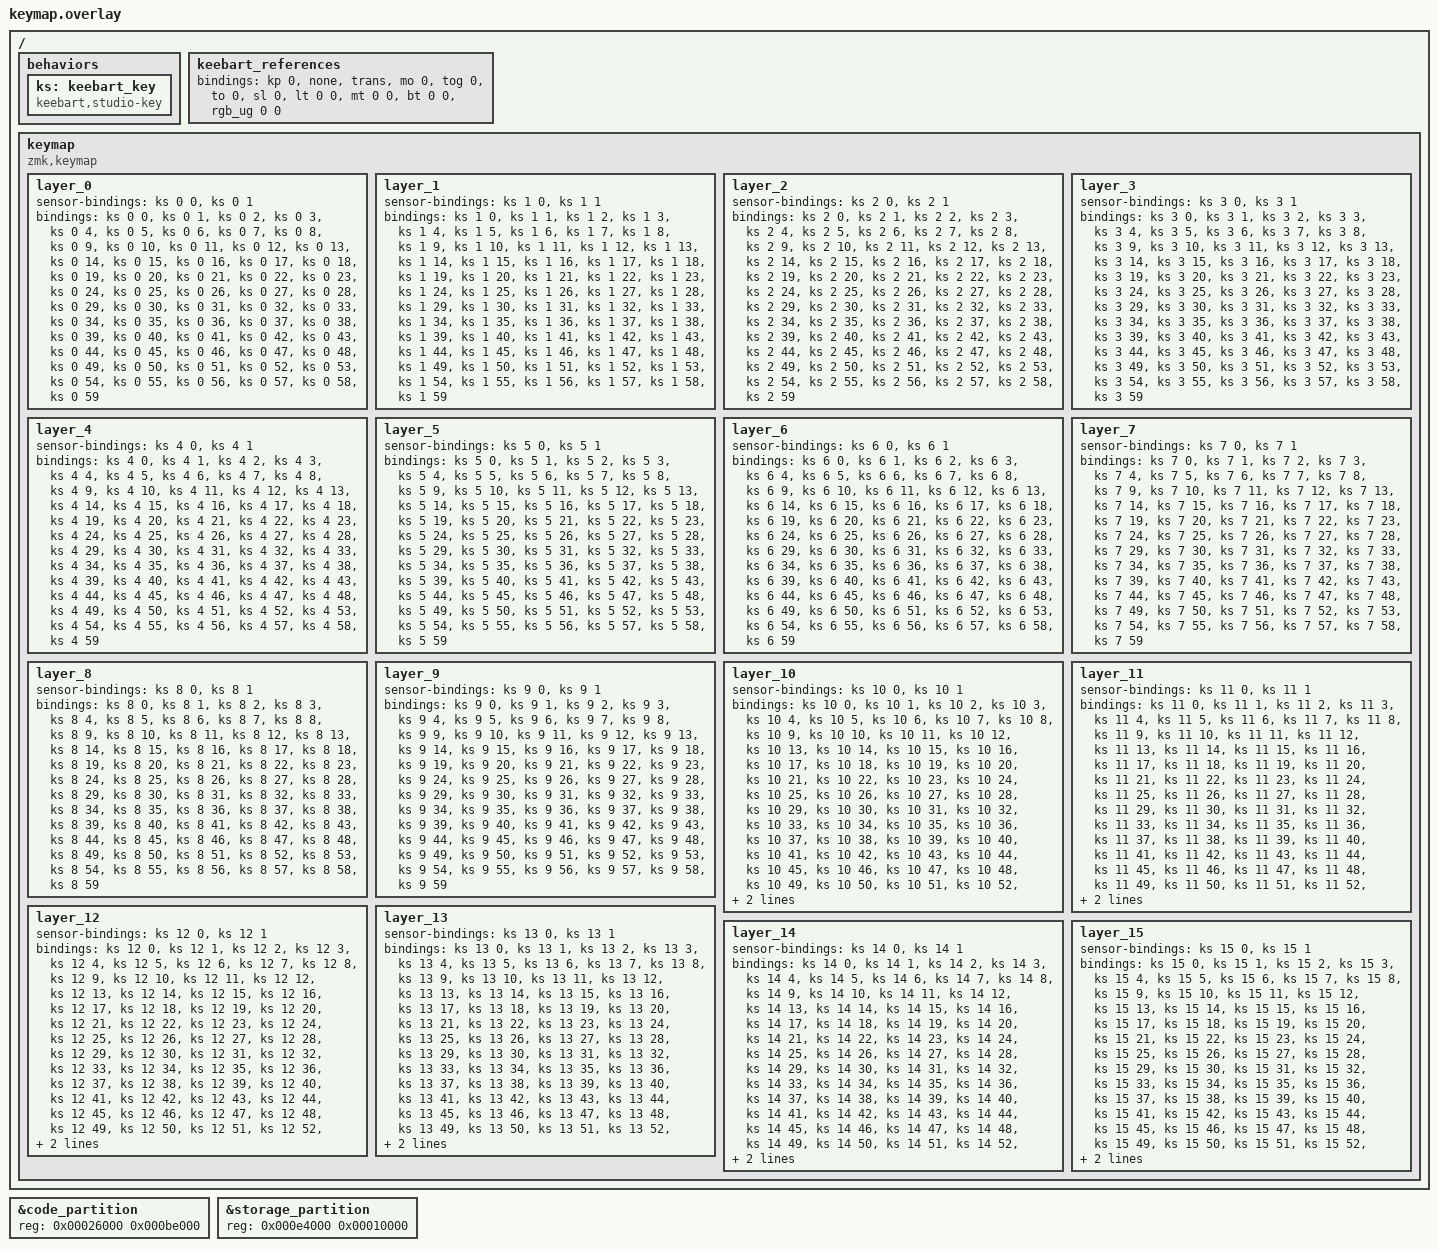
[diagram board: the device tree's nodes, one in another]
#include <behaviors.dtsi>
/ { /delete-node/ keymap; /delete-node/ conditional_layers; };
/ {
 behaviors { ks: keebart_key { compatible = "keebart,studio-key"; #binding-cells = <2>; #sensor-binding-cells = <2>; }; };
 keebart_references { bindings = <&kp 0 &none &trans &mo 0 &tog 0 &to 0 &sl 0 &lt 0 0 &mt 0 0 &bt 0 0 &rgb_ug 0 0>; };
 keymap { compatible = "zmk,keymap";
 layer_0 { sensor-bindings = <&ks 0 0 &ks 0 1>; bindings = <&ks 0 0 &ks 0 1 &ks 0 2 &ks 0 3 &ks 0 4 &ks 0 5 &ks 0 6 &ks 0 7 &ks 0 8 &ks 0 9 &ks 0 10 &ks 0 11 &ks 0 12 &ks 0 13 &ks 0 14 &ks 0 15 &ks 0 16 &ks 0 17 &ks 0 18 &ks 0 19 &ks 0 20 &ks 0 21 &ks 0 22 &ks 0 23 &ks 0 24 &ks 0 25 &ks 0 26 &ks 0 27 &ks 0 28 &ks 0 29 &ks 0 30 &ks 0 31 &ks 0 32 &ks 0 33 &ks 0 34 &ks 0 35 &ks 0 36 &ks 0 37 &ks 0 38 &ks 0 39 &ks 0 40 &ks 0 41 &ks 0 42 &ks 0 43 &ks 0 44 &ks 0 45 &ks 0 46 &ks 0 47 &ks 0 48 &ks 0 49 &ks 0 50 &ks 0 51 &ks 0 52 &ks 0 53 &ks 0 54 &ks 0 55 &ks 0 56 &ks 0 57 &ks 0 58 &ks 0 59>; };
 layer_1 { sensor-bindings = <&ks 1 0 &ks 1 1>; bindings = <&ks 1 0 &ks 1 1 &ks 1 2 &ks 1 3 &ks 1 4 &ks 1 5 &ks 1 6 &ks 1 7 &ks 1 8 &ks 1 9 &ks 1 10 &ks 1 11 &ks 1 12 &ks 1 13 &ks 1 14 &ks 1 15 &ks 1 16 &ks 1 17 &ks 1 18 &ks 1 19 &ks 1 20 &ks 1 21 &ks 1 22 &ks 1 23 &ks 1 24 &ks 1 25 &ks 1 26 &ks 1 27 &ks 1 28 &ks 1 29 &ks 1 30 &ks 1 31 &ks 1 32 &ks 1 33 &ks 1 34 &ks 1 35 &ks 1 36 &ks 1 37 &ks 1 38 &ks 1 39 &ks 1 40 &ks 1 41 &ks 1 42 &ks 1 43 &ks 1 44 &ks 1 45 &ks 1 46 &ks 1 47 &ks 1 48 &ks 1 49 &ks 1 50 &ks 1 51 &ks 1 52 &ks 1 53 &ks 1 54 &ks 1 55 &ks 1 56 &ks 1 57 &ks 1 58 &ks 1 59>; };
 layer_2 { sensor-bindings = <&ks 2 0 &ks 2 1>; bindings = <&ks 2 0 &ks 2 1 &ks 2 2 &ks 2 3 &ks 2 4 &ks 2 5 &ks 2 6 &ks 2 7 &ks 2 8 &ks 2 9 &ks 2 10 &ks 2 11 &ks 2 12 &ks 2 13 &ks 2 14 &ks 2 15 &ks 2 16 &ks 2 17 &ks 2 18 &ks 2 19 &ks 2 20 &ks 2 21 &ks 2 22 &ks 2 23 &ks 2 24 &ks 2 25 &ks 2 26 &ks 2 27 &ks 2 28 &ks 2 29 &ks 2 30 &ks 2 31 &ks 2 32 &ks 2 33 &ks 2 34 &ks 2 35 &ks 2 36 &ks 2 37 &ks 2 38 &ks 2 39 &ks 2 40 &ks 2 41 &ks 2 42 &ks 2 43 &ks 2 44 &ks 2 45 &ks 2 46 &ks 2 47 &ks 2 48 &ks 2 49 &ks 2 50 &ks 2 51 &ks 2 52 &ks 2 53 &ks 2 54 &ks 2 55 &ks 2 56 &ks 2 57 &ks 2 58 &ks 2 59>; };
 layer_3 { sensor-bindings = <&ks 3 0 &ks 3 1>; bindings = <&ks 3 0 &ks 3 1 &ks 3 2 &ks 3 3 &ks 3 4 &ks 3 5 &ks 3 6 &ks 3 7 &ks 3 8 &ks 3 9 &ks 3 10 &ks 3 11 &ks 3 12 &ks 3 13 &ks 3 14 &ks 3 15 &ks 3 16 &ks 3 17 &ks 3 18 &ks 3 19 &ks 3 20 &ks 3 21 &ks 3 22 &ks 3 23 &ks 3 24 &ks 3 25 &ks 3 26 &ks 3 27 &ks 3 28 &ks 3 29 &ks 3 30 &ks 3 31 &ks 3 32 &ks 3 33 &ks 3 34 &ks 3 35 &ks 3 36 &ks 3 37 &ks 3 38 &ks 3 39 &ks 3 40 &ks 3 41 &ks 3 42 &ks 3 43 &ks 3 44 &ks 3 45 &ks 3 46 &ks 3 47 &ks 3 48 &ks 3 49 &ks 3 50 &ks 3 51 &ks 3 52 &ks 3 53 &ks 3 54 &ks 3 55 &ks 3 56 &ks 3 57 &ks 3 58 &ks 3 59>; };
 layer_4 { sensor-bindings = <&ks 4 0 &ks 4 1>; bindings = <&ks 4 0 &ks 4 1 &ks 4 2 &ks 4 3 &ks 4 4 &ks 4 5 &ks 4 6 &ks 4 7 &ks 4 8 &ks 4 9 &ks 4 10 &ks 4 11 &ks 4 12 &ks 4 13 &ks 4 14 &ks 4 15 &ks 4 16 &ks 4 17 &ks 4 18 &ks 4 19 &ks 4 20 &ks 4 21 &ks 4 22 &ks 4 23 &ks 4 24 &ks 4 25 &ks 4 26 &ks 4 27 &ks 4 28 &ks 4 29 &ks 4 30 &ks 4 31 &ks 4 32 &ks 4 33 &ks 4 34 &ks 4 35 &ks 4 36 &ks 4 37 &ks 4 38 &ks 4 39 &ks 4 40 &ks 4 41 &ks 4 42 &ks 4 43 &ks 4 44 &ks 4 45 &ks 4 46 &ks 4 47 &ks 4 48 &ks 4 49 &ks 4 50 &ks 4 51 &ks 4 52 &ks 4 53 &ks 4 54 &ks 4 55 &ks 4 56 &ks 4 57 &ks 4 58 &ks 4 59>; };
 layer_5 { sensor-bindings = <&ks 5 0 &ks 5 1>; bindings = <&ks 5 0 &ks 5 1 &ks 5 2 &ks 5 3 &ks 5 4 &ks 5 5 &ks 5 6 &ks 5 7 &ks 5 8 &ks 5 9 &ks 5 10 &ks 5 11 &ks 5 12 &ks 5 13 &ks 5 14 &ks 5 15 &ks 5 16 &ks 5 17 &ks 5 18 &ks 5 19 &ks 5 20 &ks 5 21 &ks 5 22 &ks 5 23 &ks 5 24 &ks 5 25 &ks 5 26 &ks 5 27 &ks 5 28 &ks 5 29 &ks 5 30 &ks 5 31 &ks 5 32 &ks 5 33 &ks 5 34 &ks 5 35 &ks 5 36 &ks 5 37 &ks 5 38 &ks 5 39 &ks 5 40 &ks 5 41 &ks 5 42 &ks 5 43 &ks 5 44 &ks 5 45 &ks 5 46 &ks 5 47 &ks 5 48 &ks 5 49 &ks 5 50 &ks 5 51 &ks 5 52 &ks 5 53 &ks 5 54 &ks 5 55 &ks 5 56 &ks 5 57 &ks 5 58 &ks 5 59>; };
 layer_6 { sensor-bindings = <&ks 6 0 &ks 6 1>; bindings = <&ks 6 0 &ks 6 1 &ks 6 2 &ks 6 3 &ks 6 4 &ks 6 5 &ks 6 6 &ks 6 7 &ks 6 8 &ks 6 9 &ks 6 10 &ks 6 11 &ks 6 12 &ks 6 13 &ks 6 14 &ks 6 15 &ks 6 16 &ks 6 17 &ks 6 18 &ks 6 19 &ks 6 20 &ks 6 21 &ks 6 22 &ks 6 23 &ks 6 24 &ks 6 25 &ks 6 26 &ks 6 27 &ks 6 28 &ks 6 29 &ks 6 30 &ks 6 31 &ks 6 32 &ks 6 33 &ks 6 34 &ks 6 35 &ks 6 36 &ks 6 37 &ks 6 38 &ks 6 39 &ks 6 40 &ks 6 41 &ks 6 42 &ks 6 43 &ks 6 44 &ks 6 45 &ks 6 46 &ks 6 47 &ks 6 48 &ks 6 49 &ks 6 50 &ks 6 51 &ks 6 52 &ks 6 53 &ks 6 54 &ks 6 55 &ks 6 56 &ks 6 57 &ks 6 58 &ks 6 59>; };
 layer_7 { sensor-bindings = <&ks 7 0 &ks 7 1>; bindings = <&ks 7 0 &ks 7 1 &ks 7 2 &ks 7 3 &ks 7 4 &ks 7 5 &ks 7 6 &ks 7 7 &ks 7 8 &ks 7 9 &ks 7 10 &ks 7 11 &ks 7 12 &ks 7 13 &ks 7 14 &ks 7 15 &ks 7 16 &ks 7 17 &ks 7 18 &ks 7 19 &ks 7 20 &ks 7 21 &ks 7 22 &ks 7 23 &ks 7 24 &ks 7 25 &ks 7 26 &ks 7 27 &ks 7 28 &ks 7 29 &ks 7 30 &ks 7 31 &ks 7 32 &ks 7 33 &ks 7 34 &ks 7 35 &ks 7 36 &ks 7 37 &ks 7 38 &ks 7 39 &ks 7 40 &ks 7 41 &ks 7 42 &ks 7 43 &ks 7 44 &ks 7 45 &ks 7 46 &ks 7 47 &ks 7 48 &ks 7 49 &ks 7 50 &ks 7 51 &ks 7 52 &ks 7 53 &ks 7 54 &ks 7 55 &ks 7 56 &ks 7 57 &ks 7 58 &ks 7 59>; };
 layer_8 { sensor-bindings = <&ks 8 0 &ks 8 1>; bindings = <&ks 8 0 &ks 8 1 &ks 8 2 &ks 8 3 &ks 8 4 &ks 8 5 &ks 8 6 &ks 8 7 &ks 8 8 &ks 8 9 &ks 8 10 &ks 8 11 &ks 8 12 &ks 8 13 &ks 8 14 &ks 8 15 &ks 8 16 &ks 8 17 &ks 8 18 &ks 8 19 &ks 8 20 &ks 8 21 &ks 8 22 &ks 8 23 &ks 8 24 &ks 8 25 &ks 8 26 &ks 8 27 &ks 8 28 &ks 8 29 &ks 8 30 &ks 8 31 &ks 8 32 &ks 8 33 &ks 8 34 &ks 8 35 &ks 8 36 &ks 8 37 &ks 8 38 &ks 8 39 &ks 8 40 &ks 8 41 &ks 8 42 &ks 8 43 &ks 8 44 &ks 8 45 &ks 8 46 &ks 8 47 &ks 8 48 &ks 8 49 &ks 8 50 &ks 8 51 &ks 8 52 &ks 8 53 &ks 8 54 &ks 8 55 &ks 8 56 &ks 8 57 &ks 8 58 &ks 8 59>; };
 layer_9 { sensor-bindings = <&ks 9 0 &ks 9 1>; bindings = <&ks 9 0 &ks 9 1 &ks 9 2 &ks 9 3 &ks 9 4 &ks 9 5 &ks 9 6 &ks 9 7 &ks 9 8 &ks 9 9 &ks 9 10 &ks 9 11 &ks 9 12 &ks 9 13 &ks 9 14 &ks 9 15 &ks 9 16 &ks 9 17 &ks 9 18 &ks 9 19 &ks 9 20 &ks 9 21 &ks 9 22 &ks 9 23 &ks 9 24 &ks 9 25 &ks 9 26 &ks 9 27 &ks 9 28 &ks 9 29 &ks 9 30 &ks 9 31 &ks 9 32 &ks 9 33 &ks 9 34 &ks 9 35 &ks 9 36 &ks 9 37 &ks 9 38 &ks 9 39 &ks 9 40 &ks 9 41 &ks 9 42 &ks 9 43 &ks 9 44 &ks 9 45 &ks 9 46 &ks 9 47 &ks 9 48 &ks 9 49 &ks 9 50 &ks 9 51 &ks 9 52 &ks 9 53 &ks 9 54 &ks 9 55 &ks 9 56 &ks 9 57 &ks 9 58 &ks 9 59>; };
 layer_10 { sensor-bindings = <&ks 10 0 &ks 10 1>; bindings = <&ks 10 0 &ks 10 1 &ks 10 2 &ks 10 3 &ks 10 4 &ks 10 5 &ks 10 6 &ks 10 7 &ks 10 8 &ks 10 9 &ks 10 10 &ks 10 11 &ks 10 12 &ks 10 13 &ks 10 14 &ks 10 15 &ks 10 16 &ks 10 17 &ks 10 18 &ks 10 19 &ks 10 20 &ks 10 21 &ks 10 22 &ks 10 23 &ks 10 24 &ks 10 25 &ks 10 26 &ks 10 27 &ks 10 28 &ks 10 29 &ks 10 30 &ks 10 31 &ks 10 32 &ks 10 33 &ks 10 34 &ks 10 35 &ks 10 36 &ks 10 37 &ks 10 38 &ks 10 39 &ks 10 40 &ks 10 41 &ks 10 42 &ks 10 43 &ks 10 44 &ks 10 45 &ks 10 46 &ks 10 47 &ks 10 48 &ks 10 49 &ks 10 50 &ks 10 51 &ks 10 52 &ks 10 53 &ks 10 54 &ks 10 55 &ks 10 56 &ks 10 57 &ks 10 58 &ks 10 59>; };
 layer_11 { sensor-bindings = <&ks 11 0 &ks 11 1>; bindings = <&ks 11 0 &ks 11 1 &ks 11 2 &ks 11 3 &ks 11 4 &ks 11 5 &ks 11 6 &ks 11 7 &ks 11 8 &ks 11 9 &ks 11 10 &ks 11 11 &ks 11 12 &ks 11 13 &ks 11 14 &ks 11 15 &ks 11 16 &ks 11 17 &ks 11 18 &ks 11 19 &ks 11 20 &ks 11 21 &ks 11 22 &ks 11 23 &ks 11 24 &ks 11 25 &ks 11 26 &ks 11 27 &ks 11 28 &ks 11 29 &ks 11 30 &ks 11 31 &ks 11 32 &ks 11 33 &ks 11 34 &ks 11 35 &ks 11 36 &ks 11 37 &ks 11 38 &ks 11 39 &ks 11 40 &ks 11 41 &ks 11 42 &ks 11 43 &ks 11 44 &ks 11 45 &ks 11 46 &ks 11 47 &ks 11 48 &ks 11 49 &ks 11 50 &ks 11 51 &ks 11 52 &ks 11 53 &ks 11 54 &ks 11 55 &ks 11 56 &ks 11 57 &ks 11 58 &ks 11 59>; };
 layer_12 { sensor-bindings = <&ks 12 0 &ks 12 1>; bindings = <&ks 12 0 &ks 12 1 &ks 12 2 &ks 12 3 &ks 12 4 &ks 12 5 &ks 12 6 &ks 12 7 &ks 12 8 &ks 12 9 &ks 12 10 &ks 12 11 &ks 12 12 &ks 12 13 &ks 12 14 &ks 12 15 &ks 12 16 &ks 12 17 &ks 12 18 &ks 12 19 &ks 12 20 &ks 12 21 &ks 12 22 &ks 12 23 &ks 12 24 &ks 12 25 &ks 12 26 &ks 12 27 &ks 12 28 &ks 12 29 &ks 12 30 &ks 12 31 &ks 12 32 &ks 12 33 &ks 12 34 &ks 12 35 &ks 12 36 &ks 12 37 &ks 12 38 &ks 12 39 &ks 12 40 &ks 12 41 &ks 12 42 &ks 12 43 &ks 12 44 &ks 12 45 &ks 12 46 &ks 12 47 &ks 12 48 &ks 12 49 &ks 12 50 &ks 12 51 &ks 12 52 &ks 12 53 &ks 12 54 &ks 12 55 &ks 12 56 &ks 12 57 &ks 12 58 &ks 12 59>; };
 layer_13 { sensor-bindings = <&ks 13 0 &ks 13 1>; bindings = <&ks 13 0 &ks 13 1 &ks 13 2 &ks 13 3 &ks 13 4 &ks 13 5 &ks 13 6 &ks 13 7 &ks 13 8 &ks 13 9 &ks 13 10 &ks 13 11 &ks 13 12 &ks 13 13 &ks 13 14 &ks 13 15 &ks 13 16 &ks 13 17 &ks 13 18 &ks 13 19 &ks 13 20 &ks 13 21 &ks 13 22 &ks 13 23 &ks 13 24 &ks 13 25 &ks 13 26 &ks 13 27 &ks 13 28 &ks 13 29 &ks 13 30 &ks 13 31 &ks 13 32 &ks 13 33 &ks 13 34 &ks 13 35 &ks 13 36 &ks 13 37 &ks 13 38 &ks 13 39 &ks 13 40 &ks 13 41 &ks 13 42 &ks 13 43 &ks 13 44 &ks 13 45 &ks 13 46 &ks 13 47 &ks 13 48 &ks 13 49 &ks 13 50 &ks 13 51 &ks 13 52 &ks 13 53 &ks 13 54 &ks 13 55 &ks 13 56 &ks 13 57 &ks 13 58 &ks 13 59>; };
 layer_14 { sensor-bindings = <&ks 14 0 &ks 14 1>; bindings = <&ks 14 0 &ks 14 1 &ks 14 2 &ks 14 3 &ks 14 4 &ks 14 5 &ks 14 6 &ks 14 7 &ks 14 8 &ks 14 9 &ks 14 10 &ks 14 11 &ks 14 12 &ks 14 13 &ks 14 14 &ks 14 15 &ks 14 16 &ks 14 17 &ks 14 18 &ks 14 19 &ks 14 20 &ks 14 21 &ks 14 22 &ks 14 23 &ks 14 24 &ks 14 25 &ks 14 26 &ks 14 27 &ks 14 28 &ks 14 29 &ks 14 30 &ks 14 31 &ks 14 32 &ks 14 33 &ks 14 34 &ks 14 35 &ks 14 36 &ks 14 37 &ks 14 38 &ks 14 39 &ks 14 40 &ks 14 41 &ks 14 42 &ks 14 43 &ks 14 44 &ks 14 45 &ks 14 46 &ks 14 47 &ks 14 48 &ks 14 49 &ks 14 50 &ks 14 51 &ks 14 52 &ks 14 53 &ks 14 54 &ks 14 55 &ks 14 56 &ks 14 57 &ks 14 58 &ks 14 59>; };
 layer_15 { sensor-bindings = <&ks 15 0 &ks 15 1>; bindings = <&ks 15 0 &ks 15 1 &ks 15 2 &ks 15 3 &ks 15 4 &ks 15 5 &ks 15 6 &ks 15 7 &ks 15 8 &ks 15 9 &ks 15 10 &ks 15 11 &ks 15 12 &ks 15 13 &ks 15 14 &ks 15 15 &ks 15 16 &ks 15 17 &ks 15 18 &ks 15 19 &ks 15 20 &ks 15 21 &ks 15 22 &ks 15 23 &ks 15 24 &ks 15 25 &ks 15 26 &ks 15 27 &ks 15 28 &ks 15 29 &ks 15 30 &ks 15 31 &ks 15 32 &ks 15 33 &ks 15 34 &ks 15 35 &ks 15 36 &ks 15 37 &ks 15 38 &ks 15 39 &ks 15 40 &ks 15 41 &ks 15 42 &ks 15 43 &ks 15 44 &ks 15 45 &ks 15 46 &ks 15 47 &ks 15 48 &ks 15 49 &ks 15 50 &ks 15 51 &ks 15 52 &ks 15 53 &ks 15 54 &ks 15 55 &ks 15 56 &ks 15 57 &ks 15 58 &ks 15 59>; };
 };
};

/* Space for two complete configurations, macros and Bluetooth settings. */
&code_partition { reg = <0x00026000 0x000be000>; };
&storage_partition { reg = <0x000e4000 0x00010000>; };
